VERSION ""

NS_ :

BS_:
BU_:
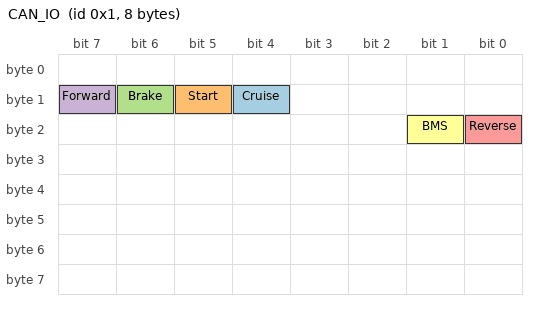
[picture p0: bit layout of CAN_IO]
BO_ 1 CAN_IO: 8 Vector__XXX
   SG_ Cruise : 12|1@1+ (1,0) [0|0] "" Vector__XXX
   SG_ Start : 13|1@1+ (1,0) [0|0] "" Vector__XXX
   SG_ Brake : 14|1@1+ (1,0) [0|0] "" Vector__XXX
   SG_ Forward : 15|1@1+ (1,0) [0|0] "" Vector__XXX
   SG_ Reverse : 16|1@1+ (1,0) [0|0] "" Vector__XXX
   SG_ BMS : 17|1@1+ (1,0) [0|0] "" Vector__XXX

BA_DEF_ BO_ "GenMsgBackgroundColor" STRING ;
BA_DEF_ BO_ "GenMsgForegroundColor" STRING ;
BA_DEF_DEF_ "GenMsgBackgroundColor" "#ffffff";
BA_DEF_DEF_ "GenMsgForegroundColor" "#000000";
VAL_ 1 Cruise 0 "Off" 1 "On";
VAL_ 1 Start 0 "Off" 1 "On";
VAL_ 1 Brake 0 "Off" 1 "On";
VAL_ 1 Forward 0 "Off" 1 "On";
VAL_ 1 Reverse 0 "Off" 1 "On";
VAL_ 1 BMS 0 "Off" 1 "On";
